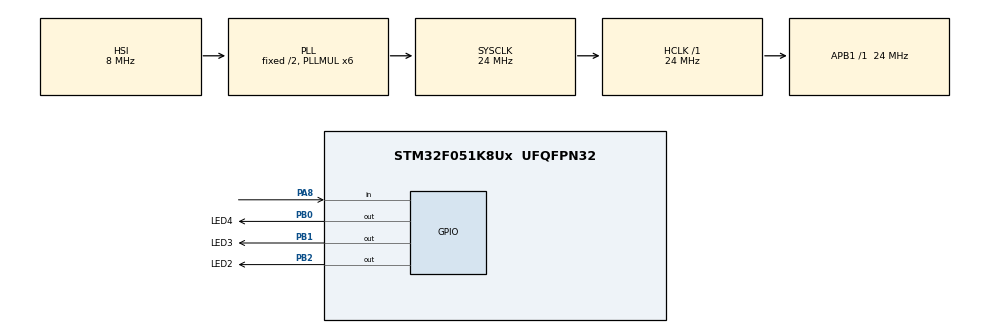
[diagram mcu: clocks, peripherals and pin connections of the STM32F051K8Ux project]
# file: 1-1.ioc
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Mcu.Family=STM32F0
Mcu.Name=STM32F051K8Ux
Mcu.Package=UFQFPN32
PA13.Mode=Serial_Wire
PA13.Signal=SYS_SWDIO
PA14.Mode=Serial_Wire
PA14.Signal=SYS_SWCLK
PA8.Signal=GPIO_Input
PB0.GPIO_Label=LED4
PB0.PinState=GPIO_PIN_SET
PB0.Signal=GPIO_Output
PB1.GPIO_Label=LED3
PB1.PinState=GPIO_PIN_RESET
PB1.Signal=GPIO_Output
PB2.GPIO_Label=LED2
PB2.PinState=GPIO_PIN_SET
PB2.Signal=GPIO_Output
PF0-OSC_IN.Mode=HSE-External-Oscillator
PF0-OSC_IN.Signal=RCC_OSC_IN
PF1-OSC_OUT.Mode=HSE-External-Oscillator
PF1-OSC_OUT.Signal=RCC_OSC_OUT
ProjectManager.HeapSize=0x200
ProjectManager.StackSize=0x400
ProjectManager.TargetToolchain=MDK-ARM V5.32
RCC.AHBFreq_Value=24000000
RCC.APB1Freq_Value=24000000
RCC.APB1TimFreq_Value=24000000
RCC.HCLKFreq_Value=24000000
RCC.PLLMUL=RCC_PLL_MUL6
RCC.SYSCLKFreq_VALUE=24000000
RCC.SYSCLKSource=RCC_SYSCLKSOURCE_PLLCLK
board=custom

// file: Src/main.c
/* USER CODE BEGIN Header */
/**
  ******************************************************************************
  * @file           : main.c
  * @brief          : Main program body
  ******************************************************************************
  * @attention
  *
  * Copyright (c) 2023 STMicroelectronics.
  * All rights reserved.
  *
  * This software is licensed under terms that can be found in the LICENSE file
  * in the root directory of this software component.
  * If no LICENSE file comes with this software, it is provided AS-IS.
  *
  ******************************************************************************
  */
/* USER CODE END Header */
#include "main.h"
#include "gpio.h"

void SystemClock_Config(void);

int main(void)
{

  /* MCU Configuration--------------------------------------------------------*/

  /* Reset of all peripherals, Initializes the Flash interface and the Systick. */
  HAL_Init();

  /* Configure the system clock */
  SystemClock_Config();

  /* Initialize all configured peripherals */
  MX_GPIO_Init();

  /* Infinite loop */
  while (1)
  {

    /* USER CODE BEGIN 3 */
    if(HAL_GPIO_ReadPin(GPIOA,GPIO_PIN_8)==1){
      HAL_Delay(100);
      if(HAL_GPIO_ReadPin(GPIOA,GPIO_PIN_8)==1){
        HAL_GPIO_TogglePin(GPIOB,LED3_Pin);
        HAL_GPIO_TogglePin(GPIOB,LED2_Pin);
        HAL_Delay(1000);
        HAL_GPIO_TogglePin(GPIOB,LED2_Pin);
        HAL_GPIO_TogglePin(GPIOB,LED4_Pin);
        HAL_Delay(1000);
        HAL_GPIO_TogglePin(GPIOB,LED4_Pin);
        HAL_GPIO_TogglePin(GPIOB,LED2_Pin);
        HAL_Delay(1000);
        HAL_GPIO_TogglePin(GPIOB,LED3_Pin);
        HAL_GPIO_TogglePin(GPIOB,LED2_Pin);
      }
    }
  }
  /* USER CODE END 3 */
}

void SystemClock_Config(void)
{
  RCC_OscInitTypeDef RCC_OscInitStruct = {0};
  RCC_ClkInitTypeDef RCC_ClkInitStruct = {0};

  /** Initializes the RCC Oscillators according to the specified parameters
  * in the RCC_OscInitTypeDef structure.
  */
  RCC_OscInitStruct.OscillatorType = RCC_OSCILLATORTYPE_HSI;
  RCC_OscInitStruct.HSIState = RCC_HSI_ON;
  RCC_OscInitStruct.HSICalibrationValue = RCC_HSICALIBRATION_DEFAULT;
  RCC_OscInitStruct.PLL.PLLState = RCC_PLL_ON;
  RCC_OscInitStruct.PLL.PLLSource = RCC_PLLSOURCE_HSI;
  RCC_OscInitStruct.PLL.PLLMUL = RCC_PLL_MUL6;
  RCC_OscInitStruct.PLL.PREDIV = RCC_PREDIV_DIV1;
  if (HAL_RCC_OscConfig(&RCC_OscInitStruct) != HAL_OK)
  {
    Error_Handler();
  }

  /** Initializes the CPU, AHB and APB buses clocks
  */
  RCC_ClkInitStruct.ClockType = RCC_CLOCKTYPE_HCLK|RCC_CLOCKTYPE_SYSCLK
                              |RCC_CLOCKTYPE_PCLK1;
  RCC_ClkInitStruct.SYSCLKSource = RCC_SYSCLKSOURCE_PLLCLK;
  RCC_ClkInitStruct.AHBCLKDivider = RCC_SYSCLK_DIV1;
  RCC_ClkInitStruct.APB1CLKDivider = RCC_HCLK_DIV1;

  if (HAL_RCC_ClockConfig(&RCC_ClkInitStruct, FLASH_LATENCY_0) != HAL_OK)
  {
    Error_Handler();
  }
}

void Error_Handler(void)
{
  __disable_irq();
  while (1)
  {
  }
}
